# ATmega32U4 register map
Vendor: Atmel; File version: 1.0
CPU: other r0p0, little endian, no MPU, no FPU, 4 interrupt priority bits
Registers are 8-bit, read-write, reset 0x0 unless marked. A register's access mark holds for its fields unless they carry their own. Offsets are from the block's base; [hi:lo] are bit positions.

## TC4 — Timer/Counter, 10-bit
Base 0x00800039
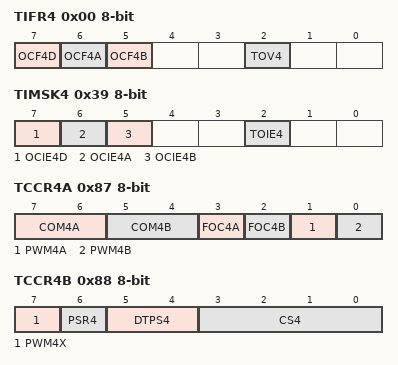
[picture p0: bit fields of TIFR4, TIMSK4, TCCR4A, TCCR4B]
0x00 TIFR4 — Timer/Counter4 Interrupt Flag register (read-only for debugger)
  [7] OCF4D — Output Compare Flag 4D
  [6] OCF4A — Output Compare Flag 4A
  [5] OCF4B — Output Compare Flag 4B
  [2] TOV4 — Timer/Counter4 Overflow Flag
0x39 TIMSK4 — Timer/Counter4 Interrupt Mask Register
  [7] OCIE4D — Timer/Counter4 Output Compare D Match Interrupt Enable
  [6] OCIE4A — Timer/Counter4 Output Compare A Match Interrupt Enable
  [5] OCIE4B — Timer/Counter4 Output Compare B Match Interrupt Enable
  [2] TOIE4 — Timer/Counter4 Overflow Interrupt Enable
0x85 TCNT4 — Timer/Counter4 Low Bytes
0x86 TC4H — Timer/Counter4
0x87 TCCR4A — Timer/Counter4 Control Register A
  [7:6] COM4A — Compare Output Mode 1A, bits
  [5:4] COM4B — Compare Output Mode 4B, bits
  [3] FOC4A — Force Output Compare Match 4A
  [2] FOC4B — Force Output Compare Match 4B
  [1] PWM4A
  [0] PWM4B
0x88 TCCR4B — Timer/Counter4 Control Register B
  [7] PWM4X — PWM Inversion Mode
  [6] PSR4 — Prescaler Reset Timer/Counter 4
  [5:4] DTPS4 — Dead Time Prescaler Bits
  [3:0] CS4 — Clock Select Bits
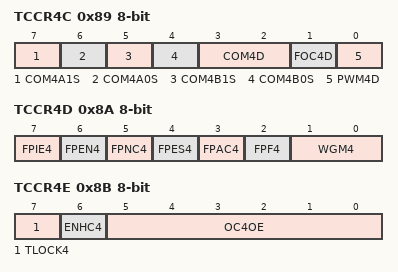
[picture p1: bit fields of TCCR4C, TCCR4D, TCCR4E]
0x89 TCCR4C — Timer/Counter 4 Control Register C
  [7] COM4A1S — Comparator A Output Mode
  [6] COM4A0S — Comparator A Output Mode
  [5] COM4B1S — Comparator B Output Mode
  [4] COM4B0S — Comparator B Output Mode
  [3:2] COM4D — Comparator D Output Mode
  [1] FOC4D — Force Output Compare Match 4D
  [0] PWM4D — Pulse Width Modulator D Enable
0x8A TCCR4D — Timer/Counter 4 Control Register D
  [7] FPIE4 — Fault Protection Interrupt Enable
  [6] FPEN4 — Fault Protection Mode Enable
  [5] FPNC4 — Fault Protection Noise Canceler
  [4] FPES4 — Fault Protection Edge Select
  [3] FPAC4 — Fault Protection Analog Comparator Enable
  [2] FPF4 — Fault Protection Interrupt Flag
  [1:0] WGM4 — Waveform Generation Mode bits
0x8B TCCR4E — Timer/Counter 4 Control Register E
  [7] TLOCK4 — Register Update Lock
  [6] ENHC4 — Enhanced Compare/PWM Mode
  [5:0] OC4OE — Output Compare Override Enable bit
0x96 OCR4A — Timer/Counter4 Output Compare Register A
0x97 OCR4B — Timer/Counter4 Output Compare Register B
0x98 OCR4C — Timer/Counter4 Output Compare Register C
0x99 OCR4D — Timer/Counter4 Output Compare Register D
0x9B DT4 — Timer/Counter 4 Dead Time Value
  [7:0] DT4L — Timer/Counter 4 Dead Time Value Bits

## TWI — Two Wire Serial Interface
Base 0x008000B8
0x00 TWBR — TWI Bit Rate register
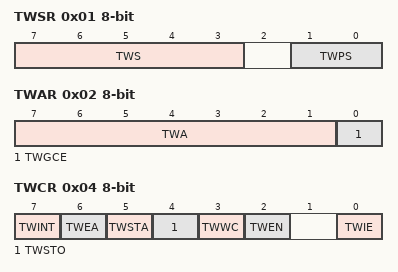
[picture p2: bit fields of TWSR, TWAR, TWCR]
0x01 TWSR — TWI Status Register
  [7:3] TWS — TWI Status
  [1:0] TWPS — TWI Prescaler
    0=1; 1=4; 2=16; 3=64
0x02 TWAR — TWI (Slave) Address register
  [7:1] TWA — TWI (Slave) Address register Bits
  [0] TWGCE — TWI General Call Recognition Enable Bit
0x03 TWDR — TWI Data register
0x04 TWCR — TWI Control Register (read-only for debugger)
  [7] TWINT — TWI Interrupt Flag
  [6] TWEA — TWI Enable Acknowledge Bit
  [5] TWSTA — TWI Start Condition Bit
  [4] TWSTO — TWI Stop Condition Bit
  [3] TWWC — TWI Write Collision Flag
  [2] TWEN — TWI Enable Bit
  [0] TWIE — TWI Interrupt Enable
0x05 TWAMR — TWI (Slave) Address Mask Register
  [7:1] TWAM

## USART1 — USART
Base 0x008000C8
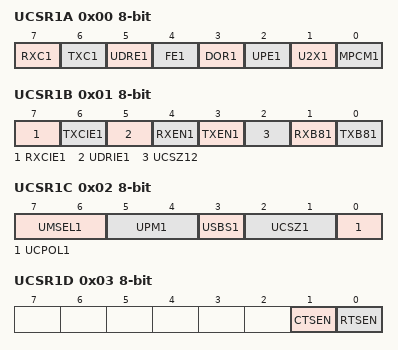
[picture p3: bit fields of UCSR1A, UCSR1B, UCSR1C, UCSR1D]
0x00 UCSR1A — USART Control and Status Register A (read-only for debugger)
  [7] RXC1 — USART Receive Complete
  [6] TXC1 — USART Transmit Complete
  [5] UDRE1 — USART Data Register Empty
  [4] FE1 — Framing Error
  [3] DOR1 — Data overRun
  [2] UPE1 — Parity Error
  [1] U2X1 — Double the USART transmission speed
  [0] MPCM1 — Multi-processor Communication Mode
0x01 UCSR1B — USART Control and Status Register B
  [7] RXCIE1 — RX Complete Interrupt Enable
  [6] TXCIE1 — TX Complete Interrupt Enable
  [5] UDRIE1 — USART Data register Empty Interrupt Enable
  [4] RXEN1 — Receiver Enable
  [3] TXEN1 — Transmitter Enable
  [2] UCSZ12 — Character Size
  [1] RXB81 — Receive Data Bit 8
  [0] TXB81 — Transmit Data Bit 8
0x02 UCSR1C — USART Control and Status Register C
  [7:6] UMSEL1 — USART Mode Select
    0=ASYNCHRONOUS_USART; 1=SYNCHRONOUS_USART; 3=MASTER_SPI
  [5:4] UPM1 — Parity Mode Bits
    0=DISABLED; 2=ENABLED_EVEN_PARITY; 3=ENABLED_ODD_PARITY
  [3] USBS1 — Stop Bit Select
    0=1_BIT; 1=2_BIT
  [2:1] UCSZ1 — Character Size
  [0] UCPOL1 — Clock Polarity
0x03 UCSR1D — USART Control and Status Register D
  [1] CTSEN — CTS Enable
  [0] RTSEN — RTS Enable
0x04 UBRR1 16-bit (reset mask 0xFF) — USART Baud Rate Register Bytes
0x06 UDR1 — USART I/O Data Register (write-only for debugger)

## USB_DEVICE — USB Device Registers
Base 0x008000D7
0x00 UHWCON
  [0] UVREGE
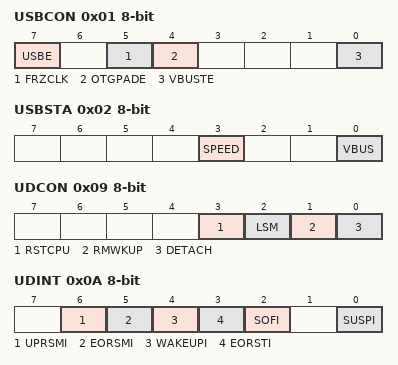
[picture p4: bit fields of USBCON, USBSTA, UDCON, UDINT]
0x01 USBCON — USB General Control Register
  [7] USBE, [5] FRZCLK, [4] OTGPADE, [0] VBUSTE
0x02 USBSTA
  [3] SPEED, [0] VBUS
0x03 USBINT
  [0] VBUSTI
0x09 UDCON
  [3] RSTCPU
  [2] LSM — USB low speed mode
  [1] RMWKUP
  [0] DETACH
0x0A UDINT
  [6] UPRSMI, [5] EORSMI, [4] WAKEUPI, [3] EORSTI, [2] SOFI, [0] SUSPI
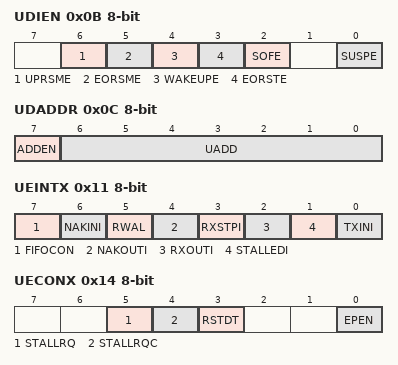
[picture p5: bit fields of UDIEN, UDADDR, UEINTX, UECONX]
0x0B UDIEN
  [6] UPRSME, [5] EORSME, [4] WAKEUPE, [3] EORSTE, [2] SOFE, [0] SUSPE
0x0C UDADDR
  [7] ADDEN, [6:0] UADD
0x0D UDFNUM 16-bit (reset mask 0xFF)
0x0F UDMFN
  [4] FNCERR
0x11 UEINTX
  [7] FIFOCON, [6] NAKINI, [5] RWAL, [4] NAKOUTI, [3] RXSTPI, [2] RXOUTI, [1] STALLEDI, [0] TXINI
0x12 UENUM
0x13 UERST
  [6:0] EPRST
0x14 UECONX
  [5] STALLRQ, [4] STALLRQC, [3] RSTDT, [0] EPEN
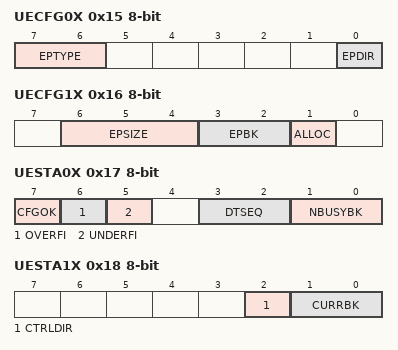
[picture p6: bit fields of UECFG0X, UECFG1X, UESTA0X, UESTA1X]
0x15 UECFG0X
  [7:6] EPTYPE, [0] EPDIR
0x16 UECFG1X
  [6:4] EPSIZE, [3:2] EPBK, [1] ALLOC
0x17 UESTA0X
  [7] CFGOK, [6] OVERFI, [5] UNDERFI, [3:2] DTSEQ, [1:0] NBUSYBK
0x18 UESTA1X
  [2] CTRLDIR, [1:0] CURRBK
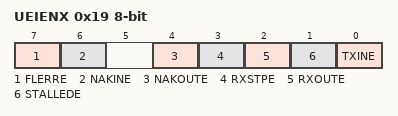
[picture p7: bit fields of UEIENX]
0x19 UEIENX
  [7] FLERRE, [6] NAKINE, [4] NAKOUTE, [3] RXSTPE, [2] RXOUTE, [1] STALLEDE, [0] TXINE
0x1A UEDATX
  [7:0] DAT
0x1B UEBCLX
0x1C UEBCHX
0x1D UEINT

## WDT — Watchdog Timer
Base 0x00800060
0x00 WDTCSR — Watchdog Timer Control Register (read-only for debugger)
  [7] WDIF — Watchdog Timeout Interrupt Flag
  [6] WDIE — Watchdog Timeout Interrupt Enable
  [4] WDCE — Watchdog Change Enable
  [3] WDE — Watch Dog Enable
  [5:0] WDP — Watchdog Timer Prescaler Bits
    0=OSCILLATOR_CYCLES_2K; 1=OSCILLATOR_CYCLES_4K; 2=OSCILLATOR_CYCLES_8K; 3=OSCILLATOR_CYCLES_16K; 4=OSCILLATOR_CYCLES_32K; 5=OSCILLATOR_CYCLES_64K; 6=OSCILLATOR_CYCLES_128K; 7=OSCILLATOR_CYCLES_256K
